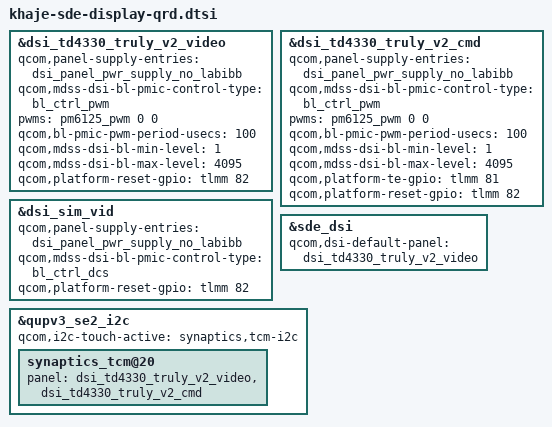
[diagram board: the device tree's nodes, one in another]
#include "khaje-sde-display.dtsi"

&dsi_td4330_truly_v2_video {
        qcom,panel-supply-entries = <&dsi_panel_pwr_supply_no_labibb>;
        qcom,mdss-dsi-bl-pmic-control-type = "bl_ctrl_pwm";
        pwms = <&pm6125_pwm 0 0>;
        qcom,bl-pmic-pwm-period-usecs = <100>;
        qcom,mdss-dsi-bl-min-level = <1>;
        qcom,mdss-dsi-bl-max-level = <4095>;
        qcom,platform-reset-gpio = <&tlmm 82 0>;
};

&dsi_td4330_truly_v2_cmd {
        qcom,panel-supply-entries = <&dsi_panel_pwr_supply_no_labibb>;
        qcom,mdss-dsi-bl-pmic-control-type = "bl_ctrl_pwm";
        pwms = <&pm6125_pwm 0 0>;
        qcom,bl-pmic-pwm-period-usecs = <100>;
        qcom,mdss-dsi-bl-min-level = <1>;
        qcom,mdss-dsi-bl-max-level = <4095>;
        qcom,platform-te-gpio = <&tlmm 81 0>;
        qcom,platform-reset-gpio = <&tlmm 82 0>;
};

&dsi_sim_vid {
        qcom,panel-supply-entries = <&dsi_panel_pwr_supply_no_labibb>;
        qcom,mdss-dsi-bl-pmic-control-type = "bl_ctrl_dcs";
        qcom,platform-reset-gpio = <&tlmm 82 0>;
};

&sde_dsi {
        qcom,dsi-default-panel = <&dsi_td4330_truly_v2_video>;
};

&qupv3_se2_i2c {
        status = "okay";
        qcom,i2c-touch-active="synaptics,tcm-i2c";
        synaptics_tcm@20 {
                panel = <&dsi_td4330_truly_v2_video &dsi_td4330_truly_v2_cmd>;
        };
};

